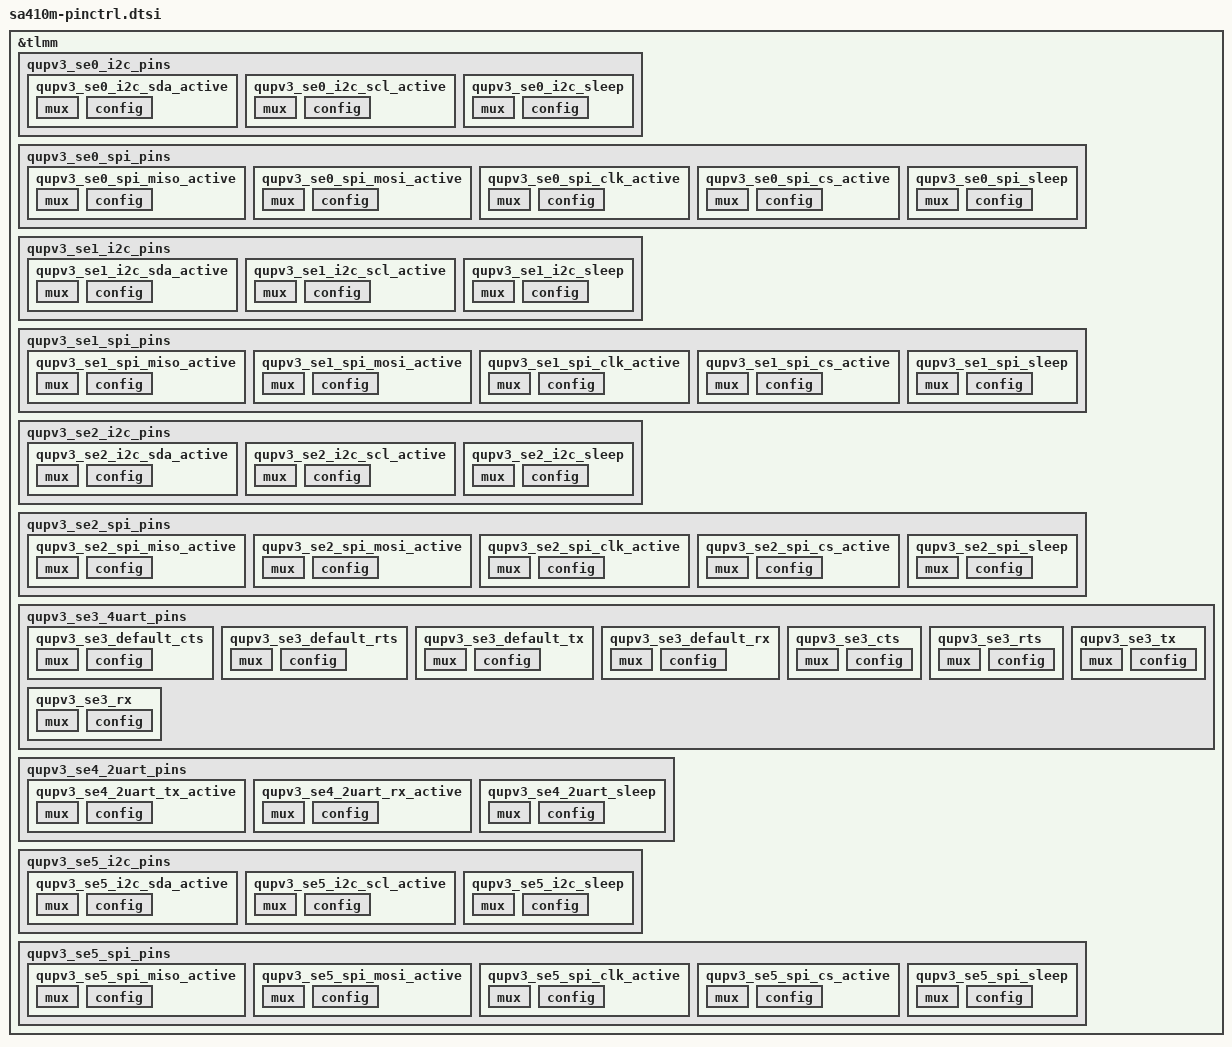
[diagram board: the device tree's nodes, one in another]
&tlmm {
	qupv3_se0_i2c_pins: qupv3_se0_i2c_pins {
		qupv3_se0_i2c_sda_active: qupv3_se0_i2c_sda_active {
			mux {
				pins = "gpio0";
				function = "qup0_se0_l0";
			};

			config {
				pins = "gpio0";
				drive-strength = <2>;
				bias-pull-up;
			};
		};

		qupv3_se0_i2c_scl_active: qupv3_se0_i2c_scl_active {
			mux {
				pins = "gpio1";
				function = "qup0_se0_l1";
			};

			config {
				pins = "gpio1";
				drive-strength = <2>;
				bias-pull-up;
			};
		};

		qupv3_se0_i2c_sleep: qupv3_se0_i2c_sleep {
			mux {
				pins = "gpio0", "gpio1";
				function = "gpio";
			};

			config {
				pins = "gpio0", "gpio1";
				drive-strength = <2>;
				bias-disable;
			};
		};
	};

	qupv3_se0_spi_pins: qupv3_se0_spi_pins {
		qupv3_se0_spi_miso_active: qupv3_se0_spi_miso_active {
			mux {
				pins = "gpio0";
				function = "qup0_se0_l0";
			};

			config {
				pins = "gpio0";
				drive-strength = <6>;
				bias-disable;
			};
		};

		qupv3_se0_spi_mosi_active: qupv3_se0_spi_mosi_active {
			mux {
				pins = "gpio1";
				function = "qup0_se0_l1";
			};

			config {
				pins = "gpio1";
				drive-strength = <6>;
				bias-disable;
			};
		};

		qupv3_se0_spi_clk_active: qupv3_se0_spi_clk_active {
			mux {
				pins = "gpio2";
				function = "qup0_se0_l2";
			};

			config {
				pins = "gpio2";
				drive-strength = <6>;
				bias-disable;
			};
		};

		qupv3_se0_spi_cs_active: qupv3_se0_spi_cs_active {
			mux {
				pins = "gpio3";
				function = "qup0_se0_l3";
			};

			config {
				pins = "gpio3";
				drive-strength = <6>;
				bias-disable;
			};
		};

		qupv3_se0_spi_sleep: qupv3_se0_spi_sleep {
			mux {
				pins = "gpio0", "gpio1",
					"gpio2", "gpio3";
				function = "gpio";
			};

			config {
				pins = "gpio0", "gpio1",
					"gpio2", "gpio3";
				drive-strength = <2>;
				bias-disable;
			};
		};
	};

	qupv3_se1_i2c_pins: qupv3_se1_i2c_pins {
		qupv3_se1_i2c_sda_active: qupv3_se1_i2c_sda_active {
			mux {
				pins = "gpio4";
				function = "qup0_se1_l0";
			};

			config {
				pins = "gpio4";
				drive-strength = <2>;
				bias-pull-up;
			};
		};

		qupv3_se1_i2c_scl_active: qupv3_se1_i2c_scl_active {
			mux {
				pins = "gpio5";
				function = "qup0_se1_l1";
			};

			config {
				pins = "gpio5";
				drive-strength = <2>;
				bias-pull-up;
			};
		};

		qupv3_se1_i2c_sleep: qupv3_se1_i2c_sleep {
			mux {
				pins = "gpio4", "gpio5";
				function = "gpio";
			};

			config {
				pins = "gpio4", "gpio5";
				drive-strength = <2>;
				bias-disable;
			};
		};
	};

	qupv3_se1_spi_pins: qupv3_se1_spi_pins {
		qupv3_se1_spi_miso_active: qupv3_se1_spi_miso_active {
			mux {
				pins = "gpio4";
				function = "qup0_se1_l0";
			};

			config {
				pins = "gpio4";
				drive-strength = <6>;
				bias-disable;
			};
		};

		qupv3_se1_spi_mosi_active: qupv3_se1_spi_mosi_active {
			mux {
				pins = "gpio5";
				function = "qup0_se1_l1";
			};

			config {
				pins = "gpio5";
				drive-strength = <6>;
				bias-disable;
			};
		};

		qupv3_se1_spi_clk_active: qupv3_se1_spi_clk_active {
			mux {
				pins = "gpio69";
				function = "qup0_se1_l2";
			};

			config {
				pins = "gpio69";
				drive-strength = <6>;
				bias-disable;
			};
		};

		qupv3_se1_spi_cs_active: qupv3_se1_spi_cs_active {
			mux {
				pins = "gpio70";
				function = "qup0_se1_l3";
			};

			config {
				pins = "gpio70";
				drive-strength = <6>;
				bias-disable;
			};
		};

		qupv3_se1_spi_sleep: qupv3_se1_spi_sleep {
			mux {
				pins = "gpio4", "gpio5",
					"gpio69", "gpio70";
				function = "gpio";
			};

			config {
				pins = "gpio4", "gpio5",
					"gpio69", "gpio70";
				drive-strength = <2>;
				bias-disable;
			};
		};
	};

	qupv3_se2_i2c_pins: qupv3_se2_i2c_pins {
		qupv3_se2_i2c_sda_active: qupv3_se2_i2c_sda_active {
			mux {
				pins = "gpio6";
				function = "qup0_se2_l0";
			};

			config {
				pins = "gpio6";
				drive-strength = <2>;
				bias-pull-up;
			};
		};

		qupv3_se2_i2c_scl_active: qupv3_se2_i2c_scl_active {
			mux {
				pins = "gpio7";
				function = "qup0_se2_l1";
			};

			config {
				pins = "gpio7";
				drive-strength = <2>;
				bias-pull-up;
			};
		};

		qupv3_se2_i2c_sleep: qupv3_se2_i2c_sleep {
			mux {
				pins = "gpio6", "gpio7";
				function = "gpio";
			};

			config {
				pins = "gpio6", "gpio7";
				drive-strength = <2>;
				bias-disable;
			};
		};
	};

	qupv3_se2_spi_pins: qupv3_se2_spi_pins {
		qupv3_se2_spi_miso_active: qupv3_se2_spi_miso_active {
			mux {
				pins = "gpio6";
				function = "qup0_se2_l0";
			};

			config {
				pins = "gpio6";
				drive-strength = <6>;
				bias-disable;
			};
		};

		qupv3_se2_spi_mosi_active: qupv3_se2_spi_mosi_active {
			mux {
				pins = "gpio7";
				function = "qup0_se2_l1";
			};

			config {
				pins = "gpio7";
				drive-strength = <6>;
				bias-disable;
			};
		};

		qupv3_se2_spi_clk_active: qupv3_se2_spi_clk_active {
			mux {
				pins = "gpio71";
				function = "qup0_se2_l2";
			};

			config {
				pins = "gpio71";
				drive-strength = <6>;
				bias-disable;
			};
		};

		qupv3_se2_spi_cs_active: qupv3_se2_spi_cs_active {
			mux {
				pins = "gpio80";
				function = "qup0_se2_l3";
			};

			config {
				pins = "gpio80";
				drive-strength = <6>;
				bias-disable;
			};
		};

		qupv3_se2_spi_sleep: qupv3_se2_spi_sleep {
			mux {
				pins = "gpio6", "gpio7",
					"gpio71", "gpio80";
				function = "gpio";
			};

			config {
				pins = "gpio6", "gpio7",
					"gpio71", "gpio80";
				drive-strength = <2>;
				bias-disable;
			};
		};
	};

	qupv3_se3_4uart_pins: qupv3_se3_4uart_pins {
		qupv3_se3_default_cts: qupv3_se3_default_cts {
			mux {
				pins = "gpio8";
				function = "gpio";
			};

			config {
				pins = "gpio8";
				drive-strength = <2>;
				bias-disable;
			};
		};

		qupv3_se3_default_rts: qupv3_se3_default_rts {
			mux {
				pins = "gpio9";
				function = "gpio";
			};

			config {
				pins = "gpio9";
				drive-strength = <2>;
				bias-pull-down;
			};
		};

		qupv3_se3_default_tx: qupv3_se3_default_tx {
			mux {
				pins = "gpio10";
				function = "gpio";
			};

			config {
				pins = "gpio10";
				drive-strength = <2>;
				bias-pull-up;
			};
		};

		qupv3_se3_default_rx: qupv3_se3_default_rx {
			mux {
				pins = "gpio11";
				function = "gpio";
			};

			config {
				pins = "gpio11";
				drive-strength = <2>;
				bias-pull-down;
			};
		};

		qupv3_se3_cts: qupv3_se3_cts {
			mux {
				pins = "gpio8";
				function = "qup0_se3_l0";
			};

			config {
				pins = "gpio8";
				drive-strength = <2>;
				bias-disable;
			};
		};

		qupv3_se3_rts: qupv3_se3_rts {
			mux {
				pins = "gpio9";
				function = "qup0_se3_l1";
			};

			config {
				pins = "gpio9";
				drive-strength = <2>;
				bias-pull-down;
			};
		};

		qupv3_se3_tx: qupv3_se3_tx {
			mux {
				pins = "gpio10";
				function = "qup0_se3_l2";
			};

			config {
				pins = "gpio10";
				drive-strength = <2>;
				bias-pull-up;
			};
		};

		qupv3_se3_rx: qupv3_se3_rx {
			mux {
				pins = "gpio11";
				function = "qup0_se3_l3";
			};

			config {
				pins = "gpio11";
				drive-strength = <2>;
				bias-disable;
			};
		};
	};

	qupv3_se4_2uart_pins: qupv3_se4_2uart_pins {
		qupv3_se4_2uart_tx_active: qupv3_se4_2uart_tx_active {
			mux {
				pins = "gpio12";
				function = "qup0_se4_l2";
			};

			config {
				pins = "gpio12";
				drive-strength = <2>;
				bias-disable;
			};
		};

		qupv3_se4_2uart_rx_active: qupv3_se4_2uart_rx_active {
			mux {
				pins = "gpio13";
				function = "qup0_se4_l3";
			};

			config {
				pins = "gpio13";
				drive-strength = <2>;
				bias-disable;
			};
		};

		qupv3_se4_2uart_sleep: qupv3_se4_2uart_sleep {
			mux {
				pins = "gpio12", "gpio13";
				function = "gpio";
			};

			config {
				pins = "gpio12", "gpio13";
				drive-strength = <2>;
				bias-disable;
			};
		};
	};

	qupv3_se5_i2c_pins: qupv3_se5_i2c_pins {
		qupv3_se5_i2c_sda_active: qupv3_se5_i2c_sda_active {
			mux {
				pins = "gpio14";
				function = "qup0_se5_l0";
			};

			config {
				pins = "gpio14";
				drive-strength = <2>;
				bias-pull-up;
			};
		};

		qupv3_se5_i2c_scl_active: qupv3_se5_i2c_scl_active {
			mux {
				pins = "gpio15";
				function = "qup0_se5_l1";
			};

			config {
				pins = "gpio15";
				drive-strength = <2>;
				bias-pull-up;
			};
		};

		qupv3_se5_i2c_sleep: qupv3_se5_i2c_sleep {
			mux {
				pins = "gpio14", "gpio15";
				function = "gpio";
			};

			config {
				pins = "gpio14", "gpio15";
				drive-strength = <2>;
				bias-disable;
			};
		};
	};

	qupv3_se5_spi_pins: qupv3_se5_spi_pins {
		qupv3_se5_spi_miso_active: qupv3_se5_spi_miso_active {
			mux {
				pins = "gpio14";
				function = "qup0_se5_l0";
			};

			config {
				pins = "gpio14";
				drive-strength = <6>;
				bias-disable;
			};
		};

		qupv3_se5_spi_mosi_active: qupv3_se5_spi_mosi_active {
			mux {
				pins = "gpio15";
				function = "qup0_se5_l1";
			};

			config {
				pins = "gpio15";
				drive-strength = <6>;
				bias-disable;
			};
		};

		qupv3_se5_spi_clk_active: qupv3_se5_spi_clk_active {
			mux {
				pins = "gpio16";
				function = "qup0_se5_l2";
			};

			config {
				pins = "gpio16";
				drive-strength = <6>;
				bias-disable;
			};
		};

		qupv3_se5_spi_cs_active: qupv3_se5_spi_cs_active {
			mux {
				pins = "gpio17";
				function = "qup0_se5_l3";
			};

			config {
				pins = "gpio17";
				drive-strength = <6>;
				bias-disable;
			};
		};

		qupv3_se5_spi_sleep: qupv3_se5_spi_sleep {
			mux {
				pins = "gpio14", "gpio15",
					"gpio16", "gpio17";
				function = "gpio";
			};

			config {
				pins = "gpio14", "gpio15",
					"gpio16", "gpio17";
				drive-strength = <2>;
				bias-disable;
			};
		};
	};
};
